AUTOSAR XML (schema 4-2-2)
package /ComponentTypes
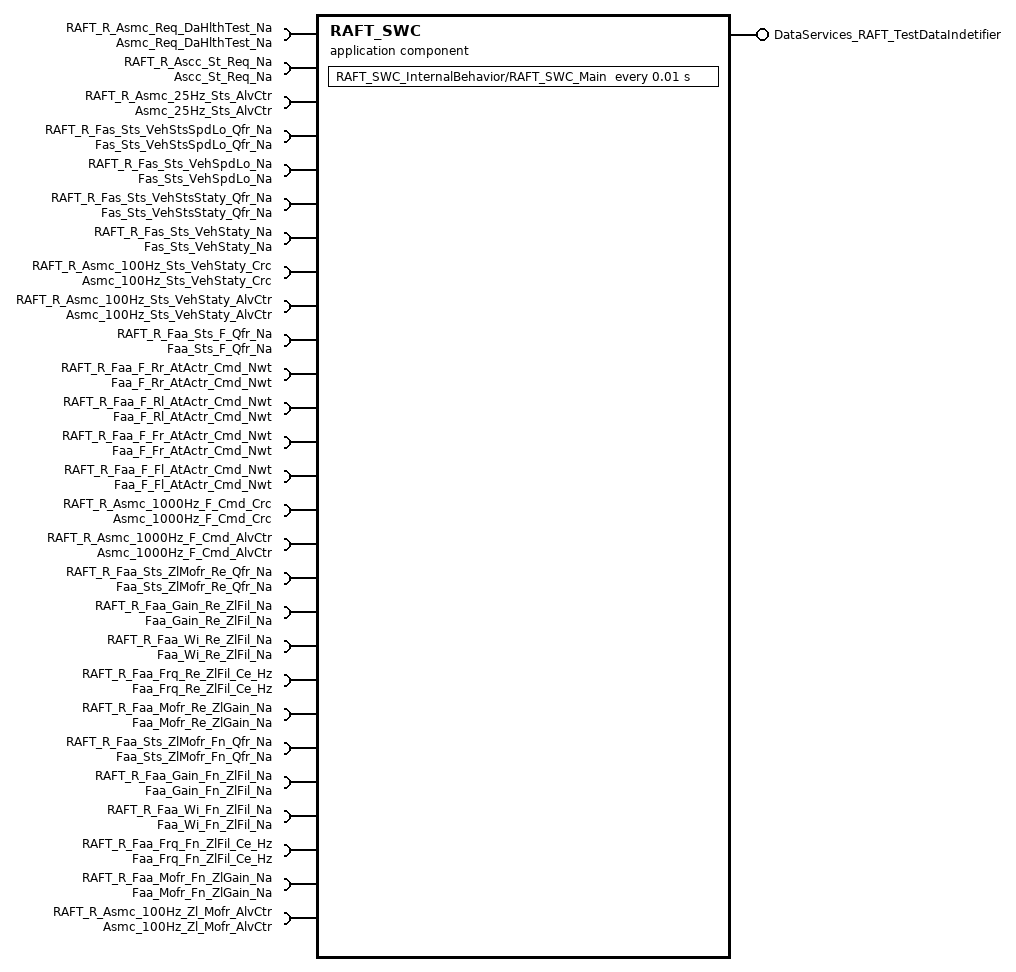
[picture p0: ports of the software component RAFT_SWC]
  application sw component type RAFT_SWC
    provide port DataServices_RAFT_TestDataIndetifier: provided-interface=DataServices_RAFT_TestDataIndetifier
      provided-com-specs:
        operation=ReadData, queue-length=1
        operation=ConditionCheckRead, queue-length=1
        operation=WriteData, queue-length=1
    27 x require port:
      RAFT_R_Asmc_Req_DaHlthTest_Na: nonqueued-receiver-com-spec{data-element=Asmc_Req_DaHlthTest_Na, filter=data-filter-type=ALWAYS, init-value=0}, required-interface=Asmc_Req_DaHlthTest_Na
      RAFT_R_Ascc_St_Req_Na: nonqueued-receiver-com-spec{data-element=Ascc_St_Req_Na, filter=data-filter-type=ALWAYS, init-value=0}, required-interface=Ascc_St_Req_Na
      RAFT_R_Asmc_25Hz_Sts_AlvCtr: nonqueued-receiver-com-spec{data-element=Asmc_25Hz_Sts_AlvCtr, filter=data-filter-type=ALWAYS, init-value=0}, required-interface=Asmc_25Hz_Sts_AlvCtr
      RAFT_R_Fas_Sts_VehStsSpdLo_Qfr_Na: nonqueued-receiver-com-spec{data-element=Fas_Sts_VehStsSpdLo_Qfr_Na, filter=data-filter-type=ALWAYS, init-value=0}, required-interface=Fas_Sts_VehStsSpdLo_Qfr_Na
      RAFT_R_Fas_Sts_VehSpdLo_Na: nonqueued-receiver-com-spec{data-element=Fas_Sts_VehSpdLo_Na, filter=data-filter-type=ALWAYS, init-value=0}, required-interface=Fas_Sts_VehSpdLo_Na
      RAFT_R_Fas_Sts_VehStsStaty_Qfr_Na: nonqueued-receiver-com-spec{data-element=Fas_Sts_VehStsStaty_Qfr_Na, filter=data-filter-type=ALWAYS, init-value=0}, required-interface=Fas_Sts_VehStsStaty_Qfr_Na
      RAFT_R_Fas_Sts_VehStaty_Na: nonqueued-receiver-com-spec{data-element=Fas_Sts_VehStaty_Na, filter=data-filter-type=ALWAYS, init-value=0}, required-interface=Fas_Sts_VehStaty_Na
      RAFT_R_Asmc_100Hz_Sts_VehStaty_Crc: nonqueued-receiver-com-spec{data-element=Asmc_100Hz_Sts_VehStaty_Crc, filter=data-filter-type=ALWAYS, init-value=0}, required-interface=Asmc_100Hz_Sts_VehStaty_Crc
      RAFT_R_Asmc_100Hz_Sts_VehStaty_AlvCtr: nonqueued-receiver-com-spec{data-element=Asmc_100Hz_Sts_VehStaty_AlvCtr, filter=data-filter-type=ALWAYS, init-value=0}, required-interface=Asmc_100Hz_Sts_VehStaty_AlvCtr
      RAFT_R_Faa_Sts_F_Qfr_Na: nonqueued-receiver-com-spec{data-element=Faa_Sts_F_Qfr_Na, filter=data-filter-type=ALWAYS, init-value=0}, required-interface=Faa_Sts_F_Qfr_Na
      RAFT_R_Faa_F_Rr_AtActr_Cmd_Nwt: nonqueued-receiver-com-spec{data-element=Faa_F_Rr_AtActr_Cmd_Nwt, filter=data-filter-type=ALWAYS, init-value=0}, required-interface=Faa_F_Rr_AtActr_Cmd_Nwt
      RAFT_R_Faa_F_Rl_AtActr_Cmd_Nwt: nonqueued-receiver-com-spec{data-element=Faa_F_Rl_AtActr_Cmd_Nwt, filter=data-filter-type=ALWAYS, init-value=0}, required-interface=Faa_F_Rl_AtActr_Cmd_Nwt
      RAFT_R_Faa_F_Fr_AtActr_Cmd_Nwt: nonqueued-receiver-com-spec{data-element=Faa_F_Fr_AtActr_Cmd_Nwt, filter=data-filter-type=ALWAYS, init-value=0}, required-interface=Faa_F_Fr_AtActr_Cmd_Nwt
      RAFT_R_Faa_F_Fl_AtActr_Cmd_Nwt: nonqueued-receiver-com-spec{data-element=Faa_F_Fl_AtActr_Cmd_Nwt, filter=data-filter-type=ALWAYS, init-value=0}, required-interface=Faa_F_Fl_AtActr_Cmd_Nwt
      RAFT_R_Asmc_1000Hz_F_Cmd_Crc: nonqueued-receiver-com-spec{data-element=Asmc_1000Hz_F_Cmd_Crc, filter=data-filter-type=ALWAYS, init-value=0}, required-interface=Asmc_1000Hz_F_Cmd_Crc
      RAFT_R_Asmc_1000Hz_F_Cmd_AlvCtr: nonqueued-receiver-com-spec{data-element=Asmc_1000Hz_F_Cmd_AlvCtr, filter=data-filter-type=ALWAYS, init-value=0}, required-interface=Asmc_1000Hz_F_Cmd_AlvCtr
      RAFT_R_Faa_Sts_ZlMofr_Re_Qfr_Na: nonqueued-receiver-com-spec{data-element=Faa_Sts_ZlMofr_Re_Qfr_Na, filter=data-filter-type=ALWAYS, init-value=0}, required-interface=Faa_Sts_ZlMofr_Re_Qfr_Na
      RAFT_R_Faa_Gain_Re_ZlFil_Na: nonqueued-receiver-com-spec{data-element=Faa_Gain_Re_ZlFil_Na, filter=data-filter-type=ALWAYS, init-value=5}, required-interface=Faa_Gain_Re_ZlFil_Na
      RAFT_R_Faa_Wi_Re_ZlFil_Na: nonqueued-receiver-com-spec{data-element=Faa_Wi_Re_ZlFil_Na, filter=data-filter-type=ALWAYS, init-value=0}, required-interface=Faa_Wi_Re_ZlFil_Na
      RAFT_R_Faa_Frq_Re_ZlFil_Ce_Hz: nonqueued-receiver-com-spec{data-element=Faa_Frq_Re_ZlFil_Ce_Hz, filter=data-filter-type=ALWAYS, init-value=5}, required-interface=Faa_Frq_Re_ZlFil_Ce_Hz
      RAFT_R_Faa_Mofr_Re_ZlGain_Na: nonqueued-receiver-com-spec{data-element=Faa_Mofr_Re_ZlGain_Na, filter=data-filter-type=ALWAYS, init-value=0}, required-interface=Faa_Mofr_Re_ZlGain_Na
      RAFT_R_Faa_Sts_ZlMofr_Fn_Qfr_Na: nonqueued-receiver-com-spec{data-element=Faa_Sts_ZlMofr_Fn_Qfr_Na, filter=data-filter-type=ALWAYS, init-value=0}, required-interface=Faa_Sts_ZlMofr_Fn_Qfr_Na
      RAFT_R_Faa_Gain_Fn_ZlFil_Na: nonqueued-receiver-com-spec{data-element=Faa_Gain_Fn_ZlFil_Na, filter=data-filter-type=ALWAYS, init-value=5}, required-interface=Faa_Gain_Fn_ZlFil_Na
      RAFT_R_Faa_Wi_Fn_ZlFil_Na: nonqueued-receiver-com-spec{data-element=Faa_Wi_Fn_ZlFil_Na, filter=data-filter-type=ALWAYS, init-value=0}, required-interface=Faa_Wi_Fn_ZlFil_Na
      RAFT_R_Faa_Frq_Fn_ZlFil_Ce_Hz: nonqueued-receiver-com-spec{data-element=Faa_Frq_Fn_ZlFil_Ce_Hz, filter=data-filter-type=ALWAYS, init-value=5}, required-interface=Faa_Frq_Fn_ZlFil_Ce_Hz
      RAFT_R_Faa_Mofr_Fn_ZlGain_Na: nonqueued-receiver-com-spec{data-element=Faa_Mofr_Fn_ZlGain_Na, filter=data-filter-type=ALWAYS, init-value=0}, required-interface=Faa_Mofr_Fn_ZlGain_Na
      RAFT_R_Asmc_100Hz_Zl_Mofr_AlvCtr: nonqueued-receiver-com-spec{data-element=Asmc_100Hz_Zl_Mofr_AlvCtr, filter=data-filter-type=ALWAYS, init-value=0}, required-interface=Asmc_100Hz_Zl_Mofr_AlvCtr
    behavior RAFT_SWC_InternalBehavior
      timing event TMT_RAFT_SWC_Main: start-on-event=RAFT_SWC_InternalBehavior/RAFT_SWC_Main, period=0.01
      init event RAFT_SWC_InitEvent: start-on-event=RAFT_SWC_Init
      operation invoked event OIT_DataServices_RAFT_TestDataIndetifier_WriteData_DataServices_RAFT_TestDataIndetifier_WriteData: start-on-event=DataServices_RAFT_TestDataIndetifier_WriteData, operation=DataServices_RAFT_TestDataIndetifier.WriteData
      operation invoked event OIT_DataServices_RAFT_TestDataIndetifier_ConditionCheckRead_DataServices_RAFT_TestDataIndetifier_ConditionCheckRead: start-on-event=DataServices_RAFT_TestDataIndetifier_ConditionCheckRead, operation=DataServices_RAFT_TestDataIndetifier.ConditionCheckRead
      operation invoked event OIT_DataServices_RAFT_TestDataIndetifier_ReadData_DataServices_RAFT_TestDataIndetifier_ReadData: start-on-event=DataServices_RAFT_TestDataIndetifier_ReadData, operation=DataServices_RAFT_TestDataIndetifier.ReadData
      port-api-options:
        enable-take-address=false, indirect-api=false, port=DataServices_RAFT_TestDataIndetifier
        enable-take-address=false, indirect-api=false, port=RAFT_R_Ascc_St_Req_Na
        enable-take-address=false, indirect-api=false, port=RAFT_R_Asmc_1000Hz_F_Cmd_AlvCtr
        enable-take-address=false, indirect-api=false, port=RAFT_R_Asmc_1000Hz_F_Cmd_Crc
        enable-take-address=false, indirect-api=false, port=RAFT_R_Asmc_100Hz_Sts_VehStaty_AlvCtr
        enable-take-address=false, indirect-api=false, port=RAFT_R_Asmc_100Hz_Sts_VehStaty_Crc
        enable-take-address=false, indirect-api=false, port=RAFT_R_Asmc_100Hz_Zl_Mofr_AlvCtr
        enable-take-address=false, indirect-api=false, port=RAFT_R_Asmc_25Hz_Sts_AlvCtr
        enable-take-address=false, indirect-api=false, port=RAFT_R_Asmc_Req_DaHlthTest_Na
        enable-take-address=false, indirect-api=false, port=RAFT_R_Faa_F_Fl_AtActr_Cmd_Nwt
        enable-take-address=false, indirect-api=false, port=RAFT_R_Faa_F_Fr_AtActr_Cmd_Nwt
        enable-take-address=false, indirect-api=false, port=RAFT_R_Faa_F_Rl_AtActr_Cmd_Nwt
        enable-take-address=false, indirect-api=false, port=RAFT_R_Faa_F_Rr_AtActr_Cmd_Nwt
        enable-take-address=false, indirect-api=false, port=RAFT_R_Faa_Frq_Fn_ZlFil_Ce_Hz
        enable-take-address=false, indirect-api=false, port=RAFT_R_Faa_Frq_Re_ZlFil_Ce_Hz
        enable-take-address=false, indirect-api=false, port=RAFT_R_Faa_Gain_Fn_ZlFil_Na
        enable-take-address=false, indirect-api=false, port=RAFT_R_Faa_Gain_Re_ZlFil_Na
        enable-take-address=false, indirect-api=false, port=RAFT_R_Faa_Mofr_Fn_ZlGain_Na
        enable-take-address=false, indirect-api=false, port=RAFT_R_Faa_Mofr_Re_ZlGain_Na
        enable-take-address=false, indirect-api=false, port=RAFT_R_Faa_Sts_F_Qfr_Na
        enable-take-address=false, indirect-api=false, port=RAFT_R_Faa_Sts_ZlMofr_Fn_Qfr_Na
        enable-take-address=false, indirect-api=false, port=RAFT_R_Faa_Sts_ZlMofr_Re_Qfr_Na
        enable-take-address=false, indirect-api=false, port=RAFT_R_Faa_Wi_Fn_ZlFil_Na
        enable-take-address=false, indirect-api=false, port=RAFT_R_Faa_Wi_Re_ZlFil_Na
        enable-take-address=false, indirect-api=false, port=RAFT_R_Fas_Sts_VehSpdLo_Na
        enable-take-address=false, indirect-api=false, port=RAFT_R_Fas_Sts_VehStaty_Na
        enable-take-address=false, indirect-api=false, port=RAFT_R_Fas_Sts_VehStsSpdLo_Qfr_Na
        enable-take-address=false, indirect-api=false, port=RAFT_R_Fas_Sts_VehStsStaty_Qfr_Na
      6 x runnable:
        RAFT_SWC_Main
          data-read-access:
            27 x access:
              READ_RAFT_R_Asmc_Req_DaHlthTest_Na_Asmc_Req_DaHlthTest_Na: accessed-variable=RAFT_R_Asmc_Req_DaHlthTest_Na.Asmc_Req_DaHlthTest_Na
              READ_RAFT_R_Ascc_St_Req_Na_Ascc_St_Req_Na: accessed-variable=RAFT_R_Ascc_St_Req_Na.Ascc_St_Req_Na
              READ_RAFT_R_Asmc_25Hz_Sts_AlvCtr_Asmc_25Hz_Sts_AlvCtr: accessed-variable=RAFT_R_Asmc_25Hz_Sts_AlvCtr.Asmc_25Hz_Sts_AlvCtr
              READ_RAFT_R_Fas_Sts_VehStsSpdLo_Qfr_Na_Fas_Sts_VehStsSpdLo_Qfr_Na: accessed-variable=RAFT_R_Fas_Sts_VehStsSpdLo_Qfr_Na.Fas_Sts_VehStsSpdLo_Qfr_Na
              READ_RAFT_R_Fas_Sts_VehSpdLo_Na_Fas_Sts_VehSpdLo_Na: accessed-variable=RAFT_R_Fas_Sts_VehSpdLo_Na.Fas_Sts_VehSpdLo_Na
              READ_RAFT_R_Fas_Sts_VehStsStaty_Qfr_Na_Fas_Sts_VehStsStaty_Qfr_Na: accessed-variable=RAFT_R_Fas_Sts_VehStsStaty_Qfr_Na.Fas_Sts_VehStsStaty_Qfr_Na
              READ_RAFT_R_Fas_Sts_VehStaty_Na_Fas_Sts_VehStaty_Na: accessed-variable=RAFT_R_Fas_Sts_VehStaty_Na.Fas_Sts_VehStaty_Na
              READ_RAFT_R_Asmc_100Hz_Sts_VehStaty_Crc_Asmc_100Hz_Sts_VehStaty_Crc: accessed-variable=RAFT_R_Asmc_100Hz_Sts_VehStaty_Crc.Asmc_100Hz_Sts_VehStaty_Crc
              READ_RAFT_R_Asmc_100Hz_Sts_VehStaty_AlvCtr_Asmc_100Hz_Sts_VehStaty_AlvCtr: accessed-variable=RAFT_R_Asmc_100Hz_Sts_VehStaty_AlvCtr.Asmc_100Hz_Sts_VehStaty_AlvCtr
              READ_RAFT_R_Faa_Sts_F_Qfr_Na_Faa_Sts_F_Qfr_Na: accessed-variable=RAFT_R_Faa_Sts_F_Qfr_Na.Faa_Sts_F_Qfr_Na
              READ_RAFT_R_Faa_F_Rr_AtActr_Cmd_Nwt_Faa_F_Rr_AtActr_Cmd_Nwt: accessed-variable=RAFT_R_Faa_F_Rr_AtActr_Cmd_Nwt.Faa_F_Rr_AtActr_Cmd_Nwt
              READ_RAFT_R_Faa_F_Rl_AtActr_Cmd_Nwt_Faa_F_Rl_AtActr_Cmd_Nwt: accessed-variable=RAFT_R_Faa_F_Rl_AtActr_Cmd_Nwt.Faa_F_Rl_AtActr_Cmd_Nwt
              READ_RAFT_R_Faa_F_Fr_AtActr_Cmd_Nwt_Faa_F_Fr_AtActr_Cmd_Nwt: accessed-variable=RAFT_R_Faa_F_Fr_AtActr_Cmd_Nwt.Faa_F_Fr_AtActr_Cmd_Nwt
              READ_RAFT_R_Faa_F_Fl_AtActr_Cmd_Nwt_Faa_F_Fl_AtActr_Cmd_Nwt: accessed-variable=RAFT_R_Faa_F_Fl_AtActr_Cmd_Nwt.Faa_F_Fl_AtActr_Cmd_Nwt
              READ_RAFT_R_Asmc_1000Hz_F_Cmd_Crc_Asmc_1000Hz_F_Cmd_Crc: accessed-variable=RAFT_R_Asmc_1000Hz_F_Cmd_Crc.Asmc_1000Hz_F_Cmd_Crc
              READ_RAFT_R_Asmc_1000Hz_F_Cmd_AlvCtr_Asmc_1000Hz_F_Cmd_AlvCtr: accessed-variable=RAFT_R_Asmc_1000Hz_F_Cmd_AlvCtr.Asmc_1000Hz_F_Cmd_AlvCtr
              READ_RAFT_R_Faa_Sts_ZlMofr_Re_Qfr_Na_Faa_Sts_ZlMofr_Re_Qfr_Na: accessed-variable=RAFT_R_Faa_Sts_ZlMofr_Re_Qfr_Na.Faa_Sts_ZlMofr_Re_Qfr_Na
              READ_RAFT_R_Faa_Gain_Re_ZlFil_Na_Faa_Gain_Re_ZlFil_Na: accessed-variable=RAFT_R_Faa_Gain_Re_ZlFil_Na.Faa_Gain_Re_ZlFil_Na
              READ_RAFT_R_Faa_Wi_Re_ZlFil_Na_Faa_Wi_Re_ZlFil_Na: accessed-variable=RAFT_R_Faa_Wi_Re_ZlFil_Na.Faa_Wi_Re_ZlFil_Na
              READ_RAFT_R_Faa_Frq_Re_ZlFil_Ce_Hz_Faa_Frq_Re_ZlFil_Ce_Hz: accessed-variable=RAFT_R_Faa_Frq_Re_ZlFil_Ce_Hz.Faa_Frq_Re_ZlFil_Ce_Hz
              READ_RAFT_R_Faa_Mofr_Re_ZlGain_Na_Faa_Mofr_Re_ZlGain_Na: accessed-variable=RAFT_R_Faa_Mofr_Re_ZlGain_Na.Faa_Mofr_Re_ZlGain_Na
              READ_RAFT_R_Faa_Sts_ZlMofr_Fn_Qfr_Na_Faa_Sts_ZlMofr_Fn_Qfr_Na: accessed-variable=RAFT_R_Faa_Sts_ZlMofr_Fn_Qfr_Na.Faa_Sts_ZlMofr_Fn_Qfr_Na
              READ_RAFT_R_Faa_Gain_Fn_ZlFil_Na_Faa_Gain_Fn_ZlFil_Na: accessed-variable=RAFT_R_Faa_Gain_Fn_ZlFil_Na.Faa_Gain_Fn_ZlFil_Na
              READ_RAFT_R_Faa_Wi_Fn_ZlFil_Na_Faa_Wi_Fn_ZlFil_Na: accessed-variable=RAFT_R_Faa_Wi_Fn_ZlFil_Na.Faa_Wi_Fn_ZlFil_Na
              READ_RAFT_R_Faa_Frq_Fn_ZlFil_Ce_Hz_Faa_Frq_Fn_ZlFil_Ce_Hz: accessed-variable=RAFT_R_Faa_Frq_Fn_ZlFil_Ce_Hz.Faa_Frq_Fn_ZlFil_Ce_Hz
              READ_RAFT_R_Faa_Mofr_Fn_ZlGain_Na_Faa_Mofr_Fn_ZlGain_Na: accessed-variable=RAFT_R_Faa_Mofr_Fn_ZlGain_Na.Faa_Mofr_Fn_ZlGain_Na
              READ_RAFT_R_Asmc_100Hz_Zl_Mofr_AlvCtr_Asmc_100Hz_Zl_Mofr_AlvCtr: accessed-variable=RAFT_R_Asmc_100Hz_Zl_Mofr_AlvCtr.Asmc_100Hz_Zl_Mofr_AlvCtr
        RAFT_SWC_Main
          data-receive-point-by-arguments:
            27 x access:
              REC_RAFT_R_Asmc_Req_DaHlthTest_Na_Asmc_Req_DaHlthTest_Na: accessed-variable=RAFT_R_Asmc_Req_DaHlthTest_Na.Asmc_Req_DaHlthTest_Na
              REC_RAFT_R_Ascc_St_Req_Na_Ascc_St_Req_Na: accessed-variable=RAFT_R_Ascc_St_Req_Na.Ascc_St_Req_Na
              REC_RAFT_R_Asmc_25Hz_Sts_AlvCtr_Asmc_25Hz_Sts_AlvCtr: accessed-variable=RAFT_R_Asmc_25Hz_Sts_AlvCtr.Asmc_25Hz_Sts_AlvCtr
              REC_RAFT_R_Fas_Sts_VehStsSpdLo_Qfr_Na_Fas_Sts_VehStsSpdLo_Qfr_Na: accessed-variable=RAFT_R_Fas_Sts_VehStsSpdLo_Qfr_Na.Fas_Sts_VehStsSpdLo_Qfr_Na
              REC_RAFT_R_Fas_Sts_VehSpdLo_Na_Fas_Sts_VehSpdLo_Na: accessed-variable=RAFT_R_Fas_Sts_VehSpdLo_Na.Fas_Sts_VehSpdLo_Na
              REC_RAFT_R_Fas_Sts_VehStsStaty_Qfr_Na_Fas_Sts_VehStsStaty_Qfr_Na: accessed-variable=RAFT_R_Fas_Sts_VehStsStaty_Qfr_Na.Fas_Sts_VehStsStaty_Qfr_Na
              REC_RAFT_R_Fas_Sts_VehStaty_Na_Fas_Sts_VehStaty_Na: accessed-variable=RAFT_R_Fas_Sts_VehStaty_Na.Fas_Sts_VehStaty_Na
              REC_RAFT_R_Asmc_100Hz_Sts_VehStaty_Crc_Asmc_100Hz_Sts_VehStaty_Crc: accessed-variable=RAFT_R_Asmc_100Hz_Sts_VehStaty_Crc.Asmc_100Hz_Sts_VehStaty_Crc
              REC_RAFT_R_Asmc_100Hz_Sts_VehStaty_AlvCtr_Asmc_100Hz_Sts_VehStaty_AlvCtr: accessed-variable=RAFT_R_Asmc_100Hz_Sts_VehStaty_AlvCtr.Asmc_100Hz_Sts_VehStaty_AlvCtr
              REC_RAFT_R_Faa_Sts_F_Qfr_Na_Faa_Sts_F_Qfr_Na: accessed-variable=RAFT_R_Faa_Sts_F_Qfr_Na.Faa_Sts_F_Qfr_Na
              REC_RAFT_R_Faa_F_Rr_AtActr_Cmd_Nwt_Faa_F_Rr_AtActr_Cmd_Nwt: accessed-variable=RAFT_R_Faa_F_Rr_AtActr_Cmd_Nwt.Faa_F_Rr_AtActr_Cmd_Nwt
              REC_RAFT_R_Faa_F_Rl_AtActr_Cmd_Nwt_Faa_F_Rl_AtActr_Cmd_Nwt: accessed-variable=RAFT_R_Faa_F_Rl_AtActr_Cmd_Nwt.Faa_F_Rl_AtActr_Cmd_Nwt
              REC_RAFT_R_Faa_F_Fr_AtActr_Cmd_Nwt_Faa_F_Fr_AtActr_Cmd_Nwt: accessed-variable=RAFT_R_Faa_F_Fr_AtActr_Cmd_Nwt.Faa_F_Fr_AtActr_Cmd_Nwt
              REC_RAFT_R_Faa_F_Fl_AtActr_Cmd_Nwt_Faa_F_Fl_AtActr_Cmd_Nwt: accessed-variable=RAFT_R_Faa_F_Fl_AtActr_Cmd_Nwt.Faa_F_Fl_AtActr_Cmd_Nwt
              REC_RAFT_R_Asmc_1000Hz_F_Cmd_Crc_Asmc_1000Hz_F_Cmd_Crc: accessed-variable=RAFT_R_Asmc_1000Hz_F_Cmd_Crc.Asmc_1000Hz_F_Cmd_Crc
              REC_RAFT_R_Asmc_1000Hz_F_Cmd_AlvCtr_Asmc_1000Hz_F_Cmd_AlvCtr: accessed-variable=RAFT_R_Asmc_1000Hz_F_Cmd_AlvCtr.Asmc_1000Hz_F_Cmd_AlvCtr
              REC_RAFT_R_Faa_Sts_ZlMofr_Re_Qfr_Na_Faa_Sts_ZlMofr_Re_Qfr_Na: accessed-variable=RAFT_R_Faa_Sts_ZlMofr_Re_Qfr_Na.Faa_Sts_ZlMofr_Re_Qfr_Na
              REC_RAFT_R_Faa_Gain_Re_ZlFil_Na_Faa_Gain_Re_ZlFil_Na: accessed-variable=RAFT_R_Faa_Gain_Re_ZlFil_Na.Faa_Gain_Re_ZlFil_Na
              REC_RAFT_R_Faa_Wi_Re_ZlFil_Na_Faa_Wi_Re_ZlFil_Na: accessed-variable=RAFT_R_Faa_Wi_Re_ZlFil_Na.Faa_Wi_Re_ZlFil_Na
              REC_RAFT_R_Faa_Frq_Re_ZlFil_Ce_Hz_Faa_Frq_Re_ZlFil_Ce_Hz: accessed-variable=RAFT_R_Faa_Frq_Re_ZlFil_Ce_Hz.Faa_Frq_Re_ZlFil_Ce_Hz
              REC_RAFT_R_Faa_Mofr_Re_ZlGain_Na_Faa_Mofr_Re_ZlGain_Na: accessed-variable=RAFT_R_Faa_Mofr_Re_ZlGain_Na.Faa_Mofr_Re_ZlGain_Na
              REC_RAFT_R_Faa_Sts_ZlMofr_Fn_Qfr_Na_Faa_Sts_ZlMofr_Fn_Qfr_Na: accessed-variable=RAFT_R_Faa_Sts_ZlMofr_Fn_Qfr_Na.Faa_Sts_ZlMofr_Fn_Qfr_Na
              REC_RAFT_R_Faa_Gain_Fn_ZlFil_Na_Faa_Gain_Fn_ZlFil_Na: accessed-variable=RAFT_R_Faa_Gain_Fn_ZlFil_Na.Faa_Gain_Fn_ZlFil_Na
              REC_RAFT_R_Faa_Wi_Fn_ZlFil_Na_Faa_Wi_Fn_ZlFil_Na: accessed-variable=RAFT_R_Faa_Wi_Fn_ZlFil_Na.Faa_Wi_Fn_ZlFil_Na
              REC_RAFT_R_Faa_Frq_Fn_ZlFil_Ce_Hz_Faa_Frq_Fn_ZlFil_Ce_Hz: accessed-variable=RAFT_R_Faa_Frq_Fn_ZlFil_Ce_Hz.Faa_Frq_Fn_ZlFil_Ce_Hz
              REC_RAFT_R_Faa_Mofr_Fn_ZlGain_Na_Faa_Mofr_Fn_ZlGain_Na: accessed-variable=RAFT_R_Faa_Mofr_Fn_ZlGain_Na.Faa_Mofr_Fn_ZlGain_Na
              REC_RAFT_R_Asmc_100Hz_Zl_Mofr_AlvCtr_Asmc_100Hz_Zl_Mofr_AlvCtr: accessed-variable=RAFT_R_Asmc_100Hz_Zl_Mofr_AlvCtr.Asmc_100Hz_Zl_Mofr_AlvCtr
        RAFT_SWC_Init
        DataServices_RAFT_TestDataIndetifier_WriteData
        DataServices_RAFT_TestDataIndetifier_ConditionCheckRead
        DataServices_RAFT_TestDataIndetifier_ReadData
  swc implementation RAFT_SWC_Implementation: behavior=RAFT_SWC_InternalBehavior
